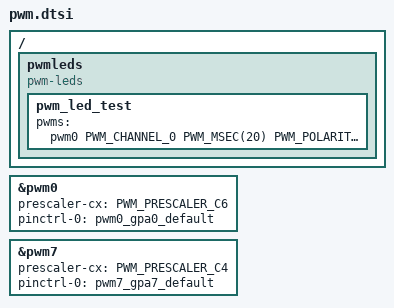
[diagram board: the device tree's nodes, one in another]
/* Copyright 2022 The ChromiumOS Authors
 * Use of this source code is governed by a BSD-style license that can be
 * found in the LICENSE file.
 */

/ {
	pwmleds {
		compatible = "pwm-leds";

		/* NOTE: &pwm number needs same with channel number */
		pwm_led_test: pwm_led_test {
			pwms = <&pwm0 PWM_CHANNEL_0 PWM_MSEC(20) PWM_POLARITY_NORMAL>;
		};
	};
};

/* pwm for test */
&pwm0 {
	status = "okay";
	prescaler-cx = <PWM_PRESCALER_C6>;
	pinctrl-0 = <&pwm0_gpa0_default>;
	pinctrl-names = "default";
};

/* pwm for fan */
&pwm7 {
	status = "okay";
	prescaler-cx = <PWM_PRESCALER_C4>;
	pinctrl-0 = <&pwm7_gpa7_default>;
	pinctrl-names = "default";
};
